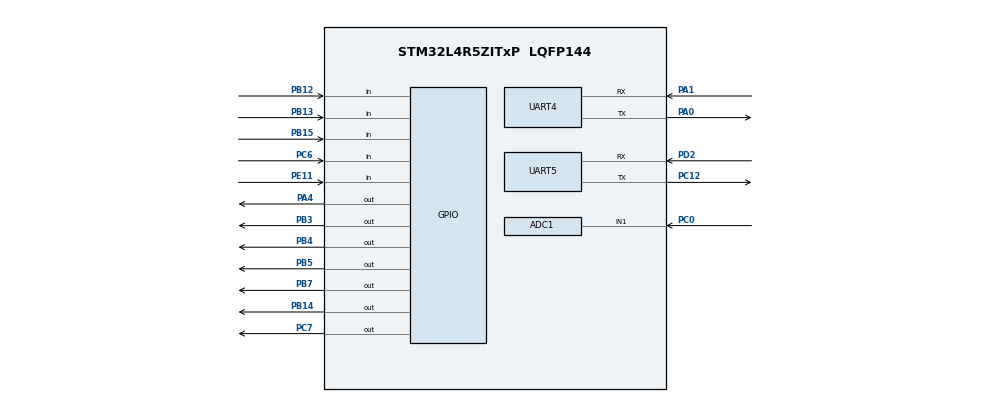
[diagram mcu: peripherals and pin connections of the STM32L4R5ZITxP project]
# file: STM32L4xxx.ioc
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ADC1.Channel-0\#ChannelRegularConversion=ADC_CHANNEL_1
ADC1.NbrOfConversionFlag=1
ADC1.OffsetNumber-0\#ChannelRegularConversion=ADC_OFFSET_NONE
ADC1.Rank-0\#ChannelRegularConversion=1
ADC1.SamplingTime-0\#ChannelRegularConversion=ADC_SAMPLETIME_2CYCLES_5
ADC1.master=1
Mcu.Family=STM32L4
Mcu.Name=STM32L4R5ZITxP
Mcu.Package=LQFP144
NVIC.PriorityGroup=NVIC_PRIORITYGROUP_4
PA0.Mode=Asynchronous
PA0.Signal=UART4_TX
PA1.Mode=Asynchronous
PA1.Signal=UART4_RX
PA4.Signal=GPIO_Output
PB12.Signal=GPIO_Input
PB13.Signal=GPIO_Input
PB14.Signal=GPIO_Output
PB15.Signal=GPIO_Input
PB3\ (JTDO/TRACESWO).Signal=GPIO_Output
PB4\ (NJTRST).Signal=GPIO_Output
PB5.Signal=GPIO_Output
PB7.Signal=GPIO_Output
PC0.Signal=ADCx_IN1
PC12.Mode=Asynchronous
PC12.Signal=UART5_TX
PC6.Signal=GPIO_Input
PC7.Signal=GPIO_Output
PD2.Mode=Asynchronous
PD2.Signal=UART5_RX
PE11.Signal=GPIO_Input
ProjectManager.HeapSize=0x200
ProjectManager.StackSize=0x400
ProjectManager.TargetToolchain=Makefile
RCC.HSE_VALUE=8000000
RCC.HSI48_VALUE=48000000
RCC.HSI_VALUE=16000000
RCC.LSE_VALUE=32768
RCC.MSI_VALUE=4000000
RCC.VCOOutputFreq_Value=32000000
SH.ADCx_IN1.0=ADC1_IN1,IN1-Single-Ended
board=custom

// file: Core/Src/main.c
/* USER CODE BEGIN Header */
/**
  ******************************************************************************
  * @file           : main.c
  * @brief          : Main program body
  ******************************************************************************
  * @attention
  *
  * Copyright (c) 2022 STMicroelectronics.
  * All rights reserved.
  *
  * This software is licensed under terms that can be found in the LICENSE file
  * in the root directory of this software component.
  * If no LICENSE file comes with this software, it is provided AS-IS.
  *
  ******************************************************************************
  */
/* USER CODE END Header */
#include "main.h"

/* USER CODE BEGIN Includes */
#include"input.h"
#include "output.h"
#include "lcd.h"
/* USER CODE END Includes */

 ADC_HandleTypeDef hadc1;

UART_HandleTypeDef huart4;
UART_HandleTypeDef huart5;

void SystemClock_Config(void);
static void MX_GPIO_Init(void);
static void MX_UART4_Init(void);
static void MX_UART5_Init(void);
static void MX_ADC1_Init(void);
/* USER CODE BEGIN PFP */
static void transmit(unsigned char buffer);
/* USER CODE END PFP */

int main(void)
{

  /* MCU Configuration--------------------------------------------------------*/

  /* Reset of all peripherals, Initializes the Flash interface and the Systick. */
  HAL_Init();

  /* Configure the system clock */
  SystemClock_Config();

  /* Initialize all configured peripherals */
  MX_GPIO_Init();
  MX_UART4_Init();
  MX_UART5_Init();
  MX_ADC1_Init();
  /* USER CODE BEGIN 2 */

  // input_init(GPIOE, GPIO_PIN_11);

  // outputinit(GPIOB, GPIO_PIN_7);
  // outputinit(GPIOC, GPIO_PIN_7);
  // outputinit(GPIOB, GPIO_PIN_14);

  lcd_init();

  /* USER CODE END 2 */

  /* Infinite loop */
  /* USER CODE BEGIN WHILE */
  HAL_StatusTypeDef status;
  unsigned char buffer;
  char str[40];

  while (1)
  {
    /* USER CODE END WHILE */

    /* USER CODE BEGIN 3 */

    // if(HAL_GPIO_ReadPin(GPIOE, GPIO_PIN_11) == GPIO_PIN_SET)
    // {
    //   HAL_GPIO_WritePin(GPIOB, GPIO_PIN_14 | GPIO_PIN_7, GPIO_PIN_SET);
    //   HAL_GPIO_WritePin(GPIOC, GPIO_PIN_7, GPIO_PIN_SET);
    //  }
    // else
    // {
    //   HAL_GPIO_WritePin(GPIOB, GPIO_PIN_14 | GPIO_PIN_7, GPIO_PIN_RESET);
    //   HAL_GPIO_WritePin(GPIOC, GPIO_PIN_7, GPIO_PIN_RESET);
    // }
    // if(HAL_GPIO_ReadPin(GPIOE, GPIO_PIN_11) == GPIO_PIN_SET)
    // {
    //   setpin(GPIOB, GPIO_PIN_14);
    //   setpin(GPIOB, GPIO_PIN_7);
    //   setpin(GPIOC, GPIO_PIN_7);
    // }
    // else
    // {
    //    clearpin(GPIOB, GPIO_PIN_7);
    //    clearpin(GPIOC, GPIO_PIN_7);
    //    clearpin(GPIOB, GPIO_PIN_14);
    // }
    // unsigned char data[] = "Lal";
    // lcd_display(data, 1);
    // lcd_display("Harrin Delina", 2);

  // status = HAL_UART_Receive(&huart5, &buffer, 1, 100);

  // switch (status)
  // {
  //   case HAL_OK:
  //       transmit(buffer);
  //       break;

  // default:
  //   break;
  // }

  /*HAL_ADC_Start(&hadc1);
  HAL_ADC_PollForConversion(&hadc1, 200);
  HAL_ADC_Stop(&hadc1);
  uint32_t value = HAL_ADC_GetValue(&hadc1);

  if(value >= 0 && value < 1000)
  {
      HAL_GPIO_WritePin(GPIOC, GPIO_PIN_7, GPIO_PIN_SET);
      HAL_GPIO_WritePin(GPIOB, GPIO_PIN_7 | GPIO_PIN_14 , GPIO_PIN_RESET);
  }
  if(value >= 1000 && value < 2000)
  {
      HAL_GPIO_WritePin(GPIOB, GPIO_PIN_7, GPIO_PIN_SET);
      HAL_GPIO_WritePin(GPIOC, GPIO_PIN_7, GPIO_PIN_RESET);
      HAL_GPIO_WritePin(GPIOB, GPIO_PIN_14, GPIO_PIN_RESET);
  }
  if(value >= 2000 && value < 3000)
  {
      HAL_GPIO_WritePin(GPIOB, GPIO_PIN_14, GPIO_PIN_SET);
      HAL_GPIO_WritePin(GPIOC, GPIO_PIN_7, GPIO_PIN_RESET);
      HAL_GPIO_WritePin(GPIOB, GPIO_PIN_7, GPIO_PIN_RESET);
  }

  sprintf(str, "Adc Value: %d\n ", value);
  HAL_UART_Transmit(&huart5, &str, sizeof(str)+2, 100);
  lcd_display(str, 1);
  HAL_Delay(2000);*/

  if(HAL_GPIO_ReadPin(GPIOC, GPIO_PIN_6) == GPIO_PIN_SET)
  {
    HAL_GPIO_WritePin(GPIOA, GPIO_PIN_4, GPIO_PIN_SET);
    HAL_GPIO_WritePin(GPIOB, GPIO_PIN_4 | GPIO_PIN_5 | GPIO_PIN_3 , GPIO_PIN_RESET);
    HAL_Delay(1000);
  }

  // if(HAL_GPIO_ReadPin(GPIOB, GPIO_PIN_15) == GPIO_PIN_SET)
  // {
  //   HAL_GPIO_WritePin(GPIOB, GPIO_PIN_4, GPIO_PIN_SET);
  //   HAL_GPIO_WritePin(GPIOA, GPIO_PIN_4, GPIO_PIN_RESET);
  //   HAL_GPIO_WritePin(GPIOB, GPIO_PIN_5 | GPIO_PIN_3 , GPIO_PIN_RESET);
  //   HAL_Delay(1000);
  // }
  // if(HAL_GPIO_ReadPin(GPIOB, GPIO_PIN_13) == GPIO_PIN_SET)
  // {
  //   HAL_GPIO_WritePin(GPIOB, GPIO_PIN_5, GPIO_PIN_SET);
  //   HAL_GPIO_WritePin(GPIOA, GPIO_PIN_4, GPIO_PIN_RESET);
  //   HAL_GPIO_WritePin(GPIOB, GPIO_PIN_4 | GPIO_PIN_3 , GPIO_PIN_RESET);
  //   HAL_Delay(1000);
  // }
  // if(HAL_GPIO_ReadPin(GPIOB, GPIO_PIN_12) == GPIO_PIN_SET)
  // {
  //   HAL_GPIO_WritePin(GPIOB, GPIO_PIN_3, GPIO_PIN_SET);
  //   HAL_GPIO_WritePin(GPIOA, GPIO_PIN_4, GPIO_PIN_RESET);
  //   HAL_GPIO_WritePin(GPIOB, GPIO_PIN_4 | GPIO_PIN_5, GPIO_PIN_RESET);
  //   HAL_Delay(1000);
  // }
}
  /* USER CODE END 3 */
}

void SystemClock_Config(void)
{
  RCC_OscInitTypeDef RCC_OscInitStruct = {0};
  RCC_ClkInitTypeDef RCC_ClkInitStruct = {0};

  /** Configure the main internal regulator output voltage
  */
  if (HAL_PWREx_ControlVoltageScaling(PWR_REGULATOR_VOLTAGE_SCALE1) != HAL_OK)
  {
    Error_Handler();
  }

  /** Initializes the RCC Oscillators according to the specified parameters
  * in the RCC_OscInitTypeDef structure.
  */
  RCC_OscInitStruct.OscillatorType = RCC_OSCILLATORTYPE_MSI;
  RCC_OscInitStruct.MSIState = RCC_MSI_ON;
  RCC_OscInitStruct.MSICalibrationValue = 0;
  RCC_OscInitStruct.MSIClockRange = RCC_MSIRANGE_6;
  RCC_OscInitStruct.PLL.PLLState = RCC_PLL_NONE;
  if (HAL_RCC_OscConfig(&RCC_OscInitStruct) != HAL_OK)
  {
    Error_Handler();
  }

  /** Initializes the CPU, AHB and APB buses clocks
  */
  RCC_ClkInitStruct.ClockType = RCC_CLOCKTYPE_HCLK|RCC_CLOCKTYPE_SYSCLK
                              |RCC_CLOCKTYPE_PCLK1|RCC_CLOCKTYPE_PCLK2;
  RCC_ClkInitStruct.SYSCLKSource = RCC_SYSCLKSOURCE_MSI;
  RCC_ClkInitStruct.AHBCLKDivider = RCC_SYSCLK_DIV1;
  RCC_ClkInitStruct.APB1CLKDivider = RCC_HCLK_DIV1;
  RCC_ClkInitStruct.APB2CLKDivider = RCC_HCLK_DIV1;

  if (HAL_RCC_ClockConfig(&RCC_ClkInitStruct, FLASH_LATENCY_0) != HAL_OK)
  {
    Error_Handler();
  }
}

static void MX_ADC1_Init(void)
{

  ADC_ChannelConfTypeDef sConfig = {0};

  /** Common config
  */
  hadc1.Instance = ADC1;
  hadc1.Init.ClockPrescaler = ADC_CLOCK_ASYNC_DIV1;
  hadc1.Init.Resolution = ADC_RESOLUTION_12B;
  hadc1.Init.DataAlign = ADC_DATAALIGN_RIGHT;
  hadc1.Init.ScanConvMode = ADC_SCAN_DISABLE;
  hadc1.Init.EOCSelection = ADC_EOC_SINGLE_CONV;
  hadc1.Init.LowPowerAutoWait = DISABLE;
  hadc1.Init.ContinuousConvMode = DISABLE;
  hadc1.Init.NbrOfConversion = 1;
  hadc1.Init.DiscontinuousConvMode = DISABLE;
  hadc1.Init.ExternalTrigConv = ADC_SOFTWARE_START;
  hadc1.Init.ExternalTrigConvEdge = ADC_EXTERNALTRIGCONVEDGE_NONE;
  hadc1.Init.DMAContinuousRequests = DISABLE;
  hadc1.Init.Overrun = ADC_OVR_DATA_PRESERVED;
  hadc1.Init.OversamplingMode = DISABLE;
  if (HAL_ADC_Init(&hadc1) != HAL_OK)
  {
    Error_Handler();
  }

  /** Configure Regular Channel
  */
  sConfig.Channel = ADC_CHANNEL_1;
  sConfig.Rank = ADC_REGULAR_RANK_1;
  sConfig.SamplingTime = ADC_SAMPLETIME_2CYCLES_5;
  sConfig.SingleDiff = ADC_SINGLE_ENDED;
  sConfig.OffsetNumber = ADC_OFFSET_NONE;
  sConfig.Offset = 0;
  if (HAL_ADC_ConfigChannel(&hadc1, &sConfig) != HAL_OK)
  {
    Error_Handler();
  }

}

static void MX_UART4_Init(void)
{

  huart4.Instance = UART4;
  huart4.Init.BaudRate = 115200;
  huart4.Init.WordLength = UART_WORDLENGTH_8B;
  huart4.Init.StopBits = UART_STOPBITS_1;
  huart4.Init.Parity = UART_PARITY_NONE;
  huart4.Init.Mode = UART_MODE_TX_RX;
  huart4.Init.HwFlowCtl = UART_HWCONTROL_NONE;
  huart4.Init.OverSampling = UART_OVERSAMPLING_16;
  huart4.Init.OneBitSampling = UART_ONE_BIT_SAMPLE_DISABLE;
  huart4.Init.ClockPrescaler = UART_PRESCALER_DIV1;
  huart4.AdvancedInit.AdvFeatureInit = UART_ADVFEATURE_NO_INIT;
  if (HAL_UART_Init(&huart4) != HAL_OK)
  {
    Error_Handler();
  }
  if (HAL_UARTEx_SetTxFifoThreshold(&huart4, UART_TXFIFO_THRESHOLD_1_8) != HAL_OK)
  {
    Error_Handler();
  }
  if (HAL_UARTEx_SetRxFifoThreshold(&huart4, UART_RXFIFO_THRESHOLD_1_8) != HAL_OK)
  {
    Error_Handler();
  }
  if (HAL_UARTEx_DisableFifoMode(&huart4) != HAL_OK)
  {
    Error_Handler();
  }

}

static void MX_UART5_Init(void)
{

  huart5.Instance = UART5;
  huart5.Init.BaudRate = 115200;
  huart5.Init.WordLength = UART_WORDLENGTH_8B;
  huart5.Init.StopBits = UART_STOPBITS_1;
  huart5.Init.Parity = UART_PARITY_NONE;
  huart5.Init.Mode = UART_MODE_TX_RX;
  huart5.Init.HwFlowCtl = UART_HWCONTROL_NONE;
  huart5.Init.OverSampling = UART_OVERSAMPLING_16;
  huart5.Init.OneBitSampling = UART_ONE_BIT_SAMPLE_DISABLE;
  huart5.Init.ClockPrescaler = UART_PRESCALER_DIV1;
  huart5.AdvancedInit.AdvFeatureInit = UART_ADVFEATURE_NO_INIT;
  if (HAL_UART_Init(&huart5) != HAL_OK)
  {
    Error_Handler();
  }
  if (HAL_UARTEx_SetTxFifoThreshold(&huart5, UART_TXFIFO_THRESHOLD_1_8) != HAL_OK)
  {
    Error_Handler();
  }
  if (HAL_UARTEx_SetRxFifoThreshold(&huart5, UART_RXFIFO_THRESHOLD_1_8) != HAL_OK)
  {
    Error_Handler();
  }
  if (HAL_UARTEx_DisableFifoMode(&huart5) != HAL_OK)
  {
    Error_Handler();
  }

}

static void MX_GPIO_Init(void)
{
  GPIO_InitTypeDef GPIO_InitStruct = {0};

  /* GPIO Ports Clock Enable */
  __HAL_RCC_GPIOC_CLK_ENABLE();
  __HAL_RCC_GPIOA_CLK_ENABLE();
  __HAL_RCC_GPIOE_CLK_ENABLE();
  __HAL_RCC_GPIOB_CLK_ENABLE();
  __HAL_RCC_GPIOD_CLK_ENABLE();

  /*Configure GPIO pin Output Level */
  HAL_GPIO_WritePin(GPIOA, GPIO_PIN_4, GPIO_PIN_RESET);

  /*Configure GPIO pin Output Level */
  HAL_GPIO_WritePin(GPIOB, GPIO_PIN_14|GPIO_PIN_3|GPIO_PIN_4|GPIO_PIN_5
                          |GPIO_PIN_7, GPIO_PIN_RESET);

  /*Configure GPIO pin Output Level */
  HAL_GPIO_WritePin(GPIOC, GPIO_PIN_7, GPIO_PIN_RESET);

  /*Configure GPIO pin : PA4 */
  GPIO_InitStruct.Pin = GPIO_PIN_4;
  GPIO_InitStruct.Mode = GPIO_MODE_OUTPUT_PP;
  GPIO_InitStruct.Pull = GPIO_NOPULL;
  GPIO_InitStruct.Speed = GPIO_SPEED_FREQ_LOW;
  HAL_GPIO_Init(GPIOA, &GPIO_InitStruct);

  /*Configure GPIO pin : PE11 */
  GPIO_InitStruct.Pin = GPIO_PIN_11;
  GPIO_InitStruct.Mode = GPIO_MODE_INPUT;
  GPIO_InitStruct.Pull = GPIO_NOPULL;
  HAL_GPIO_Init(GPIOE, &GPIO_InitStruct);

  /*Configure GPIO pins : PB12 PB13 PB15 */
  GPIO_InitStruct.Pin = GPIO_PIN_12|GPIO_PIN_13|GPIO_PIN_15;
  GPIO_InitStruct.Mode = GPIO_MODE_INPUT;
  GPIO_InitStruct.Pull = GPIO_NOPULL;
  HAL_GPIO_Init(GPIOB, &GPIO_InitStruct);

  /*Configure GPIO pins : PB14 PB3 PB4 PB5
                           PB7 */
  GPIO_InitStruct.Pin = GPIO_PIN_14|GPIO_PIN_3|GPIO_PIN_4|GPIO_PIN_5
                          |GPIO_PIN_7;
  GPIO_InitStruct.Mode = GPIO_MODE_OUTPUT_PP;
  GPIO_InitStruct.Pull = GPIO_NOPULL;
  GPIO_InitStruct.Speed = GPIO_SPEED_FREQ_LOW;
  HAL_GPIO_Init(GPIOB, &GPIO_InitStruct);

  /*Configure GPIO pin : PC6 */
  GPIO_InitStruct.Pin = GPIO_PIN_6;
  GPIO_InitStruct.Mode = GPIO_MODE_INPUT;
  GPIO_InitStruct.Pull = GPIO_NOPULL;
  HAL_GPIO_Init(GPIOC, &GPIO_InitStruct);

  /*Configure GPIO pin : PC7 */
  GPIO_InitStruct.Pin = GPIO_PIN_7;
  GPIO_InitStruct.Mode = GPIO_MODE_OUTPUT_PP;
  GPIO_InitStruct.Pull = GPIO_NOPULL;
  GPIO_InitStruct.Speed = GPIO_SPEED_FREQ_LOW;
  HAL_GPIO_Init(GPIOC, &GPIO_InitStruct);

}

void Error_Handler(void)
{
  __disable_irq();
  while (1)
  {
  }
}
